# H6 register map
Vendor: Allwinner; Series: H6; File version: 0.1
CPU: CA53 0, little endian, MPU, no FPU, 0 interrupt priority bits
Registers are 32-bit, read-write, reset 0x0 unless marked. A register's access mark holds for its fields unless they carry their own. Offsets are from the block's base; [hi:lo] are bit positions; {n}, {i} and the like mark numbered series.

## CSI_BASE
Base 0x06620000
Same registers: CSI_TOP 0x06620000, CSI_PARSER 0x06621000, CSI_DMA0 0x06623000, CSI_DMA1 0x06623100, CSI_CCI0 0x0662E000

## CE_NS
Base 0x01904000
Same registers: CE_S 0x01904800
0x00 CE_TDA — Task Descriptor Address
  [31:0] TASK
0x08 CE_ICR — Interrupt Control Register
  [3:0] TASK — Task channel0-3 interrupt enable 0: interrupt disable 1: interrupt enable
0x0C CE_ISR — Interrupt Status Register
  [3:0] TASK write-1-clears — Task channel0-3 end pending 0: not finished 1: finished It indicates if task has been completed . Write `1` to clear it.
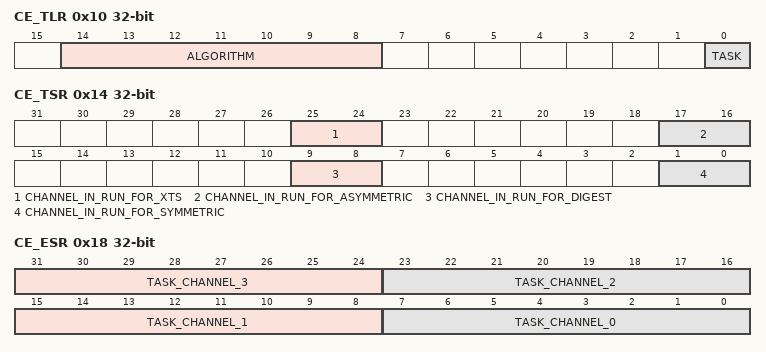
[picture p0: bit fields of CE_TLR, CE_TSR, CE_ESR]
0x10 CE_TLR — Task Load Register
  [14:8] ALGORITHM — Algorithm type, the same with type field in description common control.
  [0] TASK — Task Load When set, CE can load the descriptor of task if task FIFO is not full.
0x14 CE_TSR — Task Status Register
  [all] fields
    {v}=task_channel{v} (v=0..3)
  [25:24] CHANNEL_IN_RUN_FOR_XTS ro — indicate which channel in run for XTS. 00: task channel0 01: task channel1 10: task channel2 11: task channel3
  [17:16] CHANNEL_IN_RUN_FOR_ASYMMETRIC ro — indicate which channel in run for asymmetric. 00: task channel0 01: task channel1 10: task channel2 11: task channel3
  [9:8] CHANNEL_IN_RUN_FOR_DIGEST ro — indicate which channel in run for digest. 00: task channel0 01: task channel1 10: task channel2 11: task channel3
  [1:0] CHANNEL_IN_RUN_FOR_SYMMETRIC ro — indicate which channel in run for symmetric. 00: task channel0 01: task channel1 10: task channel2 11: task channel3
0x18 CE_ESR — Error Status Register
  [31:24] TASK_CHANNEL_3 write-1-clears — Task channel 3 error type. (the same for other channels) Bit 24: algorithm not support Bit 25: data length error Bit 26: keysram access error. Write `1` to clear. Bit 29: address invalid Bit30: key ladder configuration error other: reserved
  [23:16] TASK_CHANNEL_2 write-1-clears — Task channel 2 error type. Bit 16: algorithm not support Bit 17: data length error Bit 18: keysram access error. Write `1` to clear. Bit 21: address invalid Bit 22: key ladder configuration error other: reserved
  [15:8] TASK_CHANNEL_1 write-1-clears — Task channel 1 error type. Bit 8: algorithm not support Bit 9: data length error Bit 10: keysram access error. Write `1` to clear. Bit 13: address invalid Bit 14: key ladder configuration error other: reserved
  [7:0] TASK_CHANNEL_0 write-1-clears — Task channel 0 error type. Bit 0: algorithm not support Bit 1: data length error Bit 2: keysram access error. Write `1` to clear. Bit 5: address invalid Bit 6: key ladder configuration error other: reserved
0x24 CE_SCSA — Symmetric Algorithm DMA Current Source Address
  [31:0] SYMMETRIC ro — Symmetric algorithm current source address DMA reads.
0x28 CE_SCDA — Symmetric Algorithm DMA Current Destination Address
  [31:0] SYMMETRIC ro — Symmetric algorithm current destination address DMA writes.
0x34 CE_HCSA — HASH Algorithm DMA Current Source Address
  [31:0] HASH ro — algorithm current source address DMA reads.
0x38 CE_HCDA — HASH Algorithm DMA Current Destination Address
  [31:0] HASH ro — algorithm current destination address DMA writes.
0x44 CE_ACSA — Asymmetric Algorithm DMA Current Source Address
  [31:0] ASYMMETRIC ro — Asymmetric algorithm current source address DMA reads.
0x48 CE_ACDA — Asymmetric Algorithm DMA Current Destination Address
  [31:0] ASYMMETRIC ro — Asymmetric algorithm current destination address DMA writes.
0x54 CE_XCSA — XTS Algorithm DMA Current Source Address
  [31:0] XTS ro — algorithm current source address DMA reads.
0x58 CE_XCDA — XTS Algorithm DMA Current Destination Address
  [31:0] XTS ro — algorithm current destination address DMA writes.
